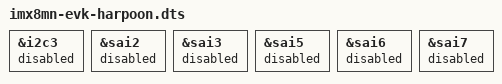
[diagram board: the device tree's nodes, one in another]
// SPDX-License-Identifier: (GPL-2.0+ OR MIT)
/*
 * Copyright 2021-2022 NXP
 */

#include "imx8mn-evk-root.dts"

&i2c3 {
	status = "disabled";
};

&sai2 {
	status = "disabled";
};

&sai3 {
	status = "disabled";
};

&sai5 {
	status = "disabled";
};

&sai6 {
	status = "disabled";
};

&sai7 {
	status = "disabled";
};
